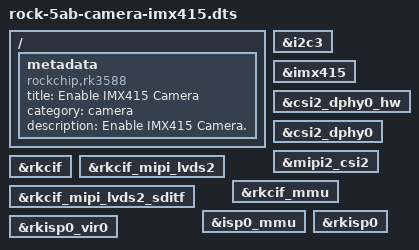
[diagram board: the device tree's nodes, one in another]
// ROCK 5A/5B Camera IMX415
/dts-v1/;
/plugin/;

/ {
	metadata {
		title = "Enable IMX415 Camera";
		compatible = "rockchip,rk3588";
		category = "camera";
		description = "Enable IMX415 Camera.";
	};

	fragment@0 {
		target = <&i2c3>;

		__overlay__ {
			status = "okay";
		};
	};

	fragment@1 {
		target = <&imx415>;

		__overlay__ {
			status = "okay";
		};
	};

	fragment@2 {
		target = <&csi2_dphy0_hw>;

		__overlay__ {
			status = "okay";
		};
	};

	fragment@3 {
		target = <&csi2_dphy0>;

		__overlay__ {
			status = "okay";
		};
	};

	fragment@4 {
		target = <&mipi2_csi2>;

		__overlay__ {
			status = "okay";
		};
	};

	fragment@5 {
		target = <&rkcif>;

		__overlay__ {
			status = "okay";
		};
	};

	fragment@6 {
		target = <&rkcif_mipi_lvds2>;

		__overlay__ {
			status = "okay";
		};
	};

	fragment@7 {
		target = <&rkcif_mipi_lvds2_sditf>;

		__overlay__ {
			status = "okay";
		};
	};

	fragment@8 {
		target = <&rkcif_mmu>;

		__overlay__ {
			status = "okay";
		};
	};

	fragment@9 {
		target = <&isp0_mmu>;

		__overlay__ {
			status = "okay";
		};
	};

	fragment@10 {
		target = <&rkisp0>;

		__overlay__ {
			status = "okay";
		};
	};

	fragment@11 {
		target = <&rkisp0_vir0>;

		__overlay__ {
			status = "okay";
		};
	};
};
